# PIC32MK0256MCJ064 device description
Architecture: MIPS; Family: PIC32MK; Series: PIC32MK
Registers are 32-bit, read-write, no defined reset value unless marked. A register's access mark holds for its fields unless they carry their own. Offsets are from the block's base; [hi:lo] are bit positions; {n}, {i} and the like mark numbered series; 'fields as' and 'values as' point back to an identical list.

## ICAP
Instances: ICAP 0x1f822000 in periph_pb2_std
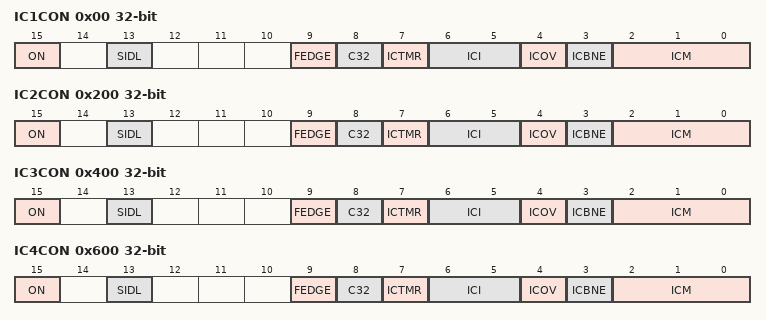
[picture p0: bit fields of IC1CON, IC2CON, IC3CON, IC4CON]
0x00 IC1CON — Input Capture x Control Register
  [15] ON — Input Capture Module Enable bit
    1=Module is enabled; 0=Disable and reset module
  [13] SIDL — Stop in Idle Control bit
    1=Halt in CPU Idle mode; 0=Continue to operate in CPU Idle mode
  [9] FEDGE — First Capture Edge Select bit
    1=Capture rising edge first; 0=Capture falling edge first
  [8] C32 — 32-bit Capture Select bit
    1=32-bit timer resource capture; 0=16-bit timer resource capture
  [7] ICTMR — Timer Select bit
    0=Timery is the counter source for capture; 1=Timerx is the counter source for capture
  [6:5] ICI — Interrupt Control bits
    3=Interrupt on every fourth capture event; 2=Interrupt on every third capture event; 1=Interrupt on every second capture event; 0=Interrupt on every capture event
  [4] ICOV — Input Capture Overflow Status Flag bit
    1=Input capture overflow is occurred; 0=No input capture overflow is occurred
  [3] ICBNE — Input Capture Buffer Not Empty Status bit
    1=Input capture buffer is not empty; at least one more capture value can be read; 0=Input capture buffer is empty
  [2:0] ICM — Input Capture Mode Select bits
    7=Interrupt-Only mode (only supported while in Sleep mode or Idle mode); 6=Simple Capture Event mode every edge; 5=Prescaled Capture Event mode every sixteenth rising edge; 4=Prescaled Capture Event mode every fourth rising edge; 3=Simple Capture Event mode every rising edge; 2=Simple Capture Event mode every falling edge; 1=Edge Detect mode every edge (rising and falling); 0=Input Capture module is disabled
0x10 IC1BUF ro
0x200 IC2CON — Input Capture x Control Register
  fields as IC1CON
0x210 IC2BUF ro
0x400 IC3CON — Input Capture x Control Register
  fields as IC1CON
0x410 IC3BUF ro
0x600 IC4CON — Input Capture x Control Register
  fields as IC1CON
0x610 IC4BUF ro
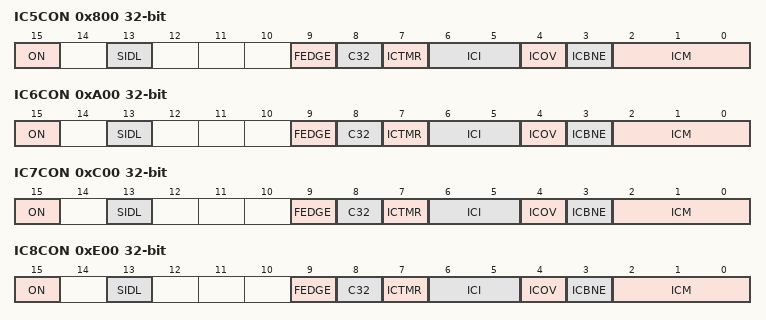
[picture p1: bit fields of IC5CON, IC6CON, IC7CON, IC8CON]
0x800 IC5CON — Input Capture x Control Register
  fields as IC1CON
0x810 IC5BUF ro
0xA00 IC6CON — Input Capture x Control Register
  fields as IC1CON
0xA10 IC6BUF ro
0xC00 IC7CON — Input Capture x Control Register
  fields as IC1CON
0xC10 IC7BUF ro
0xE00 IC8CON — Input Capture x Control Register
  fields as IC1CON
0xE10 IC8BUF ro
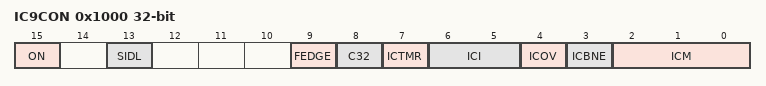
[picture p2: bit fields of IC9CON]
0x1000 IC9CON — Input Capture x Control Register
  fields as IC1CON
0x1010 IC9BUF ro

## JTAG
Instances: JTAG 0x1f801000 in periph_pb1_std
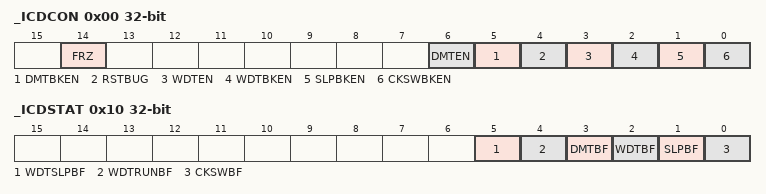
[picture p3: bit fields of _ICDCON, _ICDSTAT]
0x00 _ICDCON
  [14] FRZ, [6] DMTEN, [5] DMTBKEN, [4] RSTBUG, [3] WDTEN, [2] WDTBKEN, [1] SLPBKEN, [0] CKSWBKEN
0x10 _ICDSTAT
  [5] WDTSLPBF, [4] WDTRUNBF, [3] DMTBF, [2] WDTBF, [1] SLPBF, [0] CKSWBF

## NVM
Instances: NVM 0x1f800a00 in periph_pb1_std
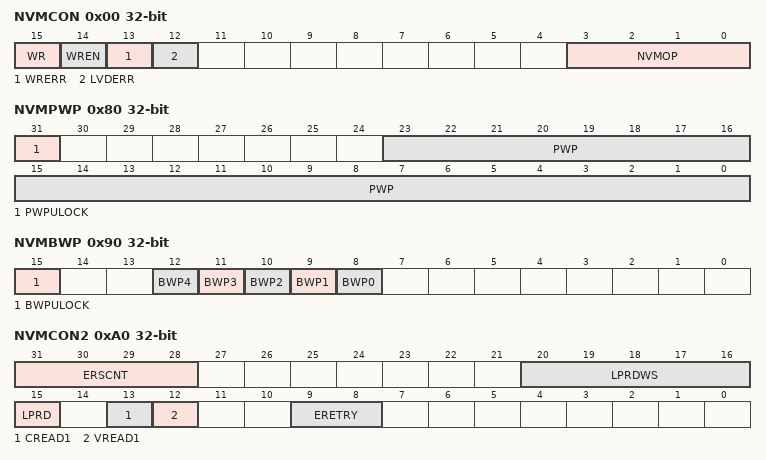
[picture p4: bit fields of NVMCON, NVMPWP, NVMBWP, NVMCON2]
0x00 NVMCON — Flash Programming Control Register
  [15] WR — Write Control bit
    1=Initiate a Flash operation; 0=Flash operation is complete or inactive
  [14] WREN — Write Enable bit
    1=Enable writes to the WR bit and disables writes to the NVMOP bits; 0=Disable writes to WR bit and enables writes to the NVMOP bits
  [13] WRERR — Write Error bit
    1=Program or erase sequence did not complete successfully; 0=Program or erase sequence completed normally
  [12] LVDERR — Low-Voltage Detect Error bit
    1=Low-voltage detected (possible data corruption if WRERR is set); 0=Voltage level is acceptable for programming
  [3:0] NVMOP — NVM Operation bits
    7=Program erase operation: erase all of program Flash memory (all pages must be unprotected); 5=Program Flash memory erase operation: erases all of Program Flash; 4=Page erase operation: erases page selected by NVMADDR; 3=Row program operation: programs row selected by NVMADDR; 2=Quad Word (128-bit) program operation: programs the 128-bit Flash word selected by NVMADDR; 1=Word program operation: programs word selected by NVMADDR; 0=No operation
0x10 NVMKEY wo — Programming Unlock Register
0x20 NVMADDR — Flash Address Register
{0x30+0x10*i} NVMDATA{i} (i=0..3) — Flash Data Register (x = 0-3
0x70 NVMSRCADDR — Source Data Address Register
0x80 NVMPWP — Program Flash Write-Protect Register
  [31] PWPULOCK — Program Flash Memory Page Write-protect Unlock bit
    1=Register is not locked and can be modified; 0=Register is locked and cannot be modified
  [23:0] PWP
0x90 NVMBWP — Flash Boot (Page) Write-Protect Register
  [15] BWPULOCK — Lower Boot Alias Write-protect Unlock bit
    1=LBWPx bits are not locked and can be modified; 0=LBWPx bits are locked and cannot be modified
  [n+8] BWP{n} (n=0..4) — Boot Alias Page {n} Write-protect bit
    1=Write protection for physical address {0x1FC00000+0x4000*n} through {0x1FC03FFF+0x4000*n} enabled; 0=Write protection for physical address {0x1FC00000+0x4000*n} through {0x1FC03FFF+0x4000*n} disabled
0xA0 NVMCON2 — Flash Programming Control Register 2
  [31:28] ERSCNT
  [20:16] LPRDWS — Wait State bits
    {v}={v} Wait States (v=0..31)
  [15] LPRD — Low-Power Read Control bit
    1=Configures Flash for Low Power reads, but with slower higher latency access times; 0=Configures Flash for faster Low Latency reads, but at higher power consumption
  [13] CREAD1 — Compare Read of Logic 1 bit
    1=Selects Erase Retry Procedure with Verify Read; 0=Selects Single Erase w/o Verify Read
  [12] VREAD1 — Verify Read of Logic 1 Control bit
    values as CREAD1
  [9:8] ERETRY — Erase Retry Control bits
    3=Erase strength for last retry cycle; 2=Erase strength for third retry cycle; 1=Erase strength for second retry cycle; 0=Erase strength for first retry cycle

## Notices in the file
Copyright (c) 2019 Microchip Technology Inc.
SPDX-License-Identifier: Apache-2.0
Licensed under the Apache License, Version 2.0 (the "License");
you may not use this file except in compliance with the License.
You may obtain a copy of the License at
http://www.apache.org/licenses/LICENSE-2.0
Unless required by applicable law or agreed to in writing, software
distributed under the License is distributed on an "AS IS" BASIS,
WITHOUT WARRANTIES OR CONDITIONS OF ANY KIND, either express or implied.
See the License for the specific language governing permissions and
limitations under the License.
